# RT58X register map
Series: ARMv8-M Mainline; File version: 1.0
CPU: CM3 r0p0, little endian, MPU, no FPU, VTOR, 3 interrupt priority bits
Registers are 32-bit, read-write, reset 0x0 unless marked. A register's access mark holds for its fields unless they carry their own. Offsets are from the block's base; [hi:lo] are bit positions.

## UART2 — UART2 Register block
Base 0xA0600000
0x00 UART2_THR_RBR_REG — uart2 thr rbr
  [7:0] THR_RBR — For write, data to be transmitted. For read, received data.
    0=B_0_to_7 (For write, data to be transmitted. For read, received data.)
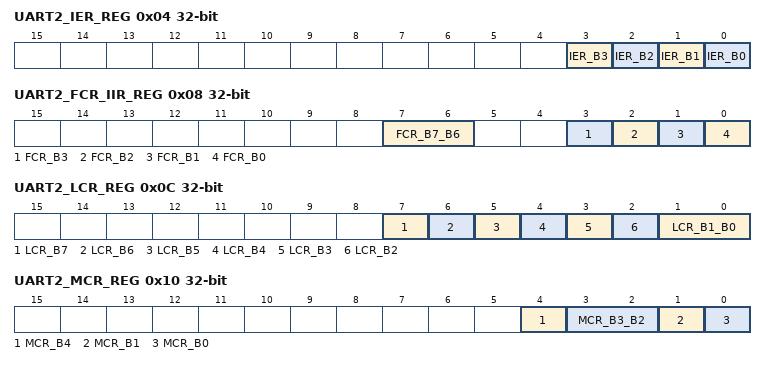
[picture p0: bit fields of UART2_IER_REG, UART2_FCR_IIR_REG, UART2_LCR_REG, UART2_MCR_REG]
0x04 UART2_IER_REG — uart2 ier
  [3] IER_B3 — Enable MODEM Status Interrupt.
    0=B_3 (Enable MODEM Status Interrupt.)
  [2] IER_B2 — Enable Receiver Line Status Interrupt.
    0=B_2 (Enable Receiver Line Status Interrupt.)
  [1] IER_B1 — Enable Transmitter Holding Register Interrupt.
    0=B_1 (Enable Transmitter Holding Register Interrupt.)
  [0] IER_B0 — Enable Received Data Available Interrupt.
    0=B_0 (Enable Received Data Available Interrupt.)
0x08 UART2_FCR_IIR_REG — uart2 fcr iir
  [7:6] FCR_B7_B6 — Receiver Trigger Level.
    0=B_6_to_7 (Receiver Trigger Level.)
  [3] FCR_B3 — DMA Mode Select. Only support 16550 Mode 1.
    0=B_3 (DMA Mode Select. Only support 16550 Mode 1.)
  [2] FCR_B2 — Transmit FIFO reset (self-clearing).
    0=B_2 (Transmit FIFO reset (self-clearing).)
  [1] FCR_B1 — Receive FIFO reset (self-clearing).
    0=B_1 (Receive FIFO reset (self-clearing).)
  [0] FCR_B0 — FIFO Enable.
    0=B_0 (FIFO Enable.)
0x0C UART2_LCR_REG — uart2 lcr
  [7] LCR_B7 — Divisor Latch Access (DLAB).
    0=B_7 (Divisor Latch Access (DLAB).)
  [6] LCR_B6 — Set Break.
    0=B_6 (Set Break.)
  [5] LCR_B5 — Stick Parity.
    0=B_5 (Stick Parity.)
  [4] LCR_B4 — Even Parity Select.
    0=B_4 (Even Parity Select.)
  [3] LCR_B3 — Parity Enable.
    0=B_3 (Parity Enable.)
  [2] LCR_B2 — Number of Stop Bits.
    0=B_2 (Number of Stop Bits.)
  [1:0] LCR_B1_B0 — Word Length Select. 0: 5-bit data 1: 6-bit data 2: 7-bit data 3: 8-bit data
    0=B_0_to_1 (Word Length Select. 0: 5-bit data 1: 6-bit data 2: 7-bit data 3: 8-bit data)
0x10 UART2_MCR_REG — uart2 mcr
  [4] MCR_B4 — Loopback mode select.
    0=B_4 (Loopback mode select.)
  [3:2] MCR_B3_B2 — Auxiliary user designated output.
    0=B_2_to_3 (Auxiliary user designated output.)
  [1] MCR_B1 — Request to Send (RTS).
    0=B_1 (Request to Send (RTS).)
  [0] MCR_B0 — Data Terminal Ready (DTR).
    0=B_0 (Data Terminal Ready (DTR).)
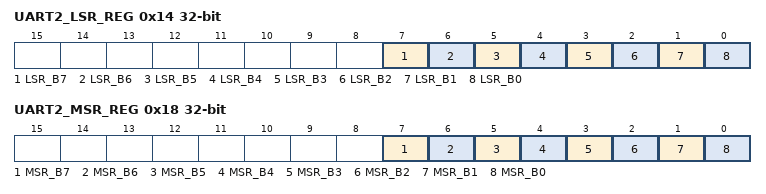
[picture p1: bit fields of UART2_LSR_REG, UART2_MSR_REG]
0x14 UART2_LSR_REG ro — uart2 lsr
  [7] LSR_B7 — Error in Receiver FIFO.
    0=B_7 (Error in Receiver FIFO.)
  [6] LSR_B6 — Transmitter Empty.
    0=B_6 (Transmitter Empty.)
  [5] LSR_B5 — Transmitter Holding Register Empty.
    0=B_5 (Transmitter Holding Register Empty.)
  [4] LSR_B4 — Break Interrupt.
    0=B_4 (Break Interrupt.)
  [3] LSR_B3 — Framing Error.
    0=B_3 (Framing Error.)
  [2] LSR_B2 — Parity Error.
    0=B_2 (Parity Error.)
  [1] LSR_B1 — Overrun Error.
    0=B_1 (Overrun Error.)
  [0] LSR_B0 — Data Ready (DR).
    0=B_0 (Data Ready (DR).)
0x18 UART2_MSR_REG ro — uart2 msr
  [7] MSR_B7 — Data Carrier Detect (DCD).
    0=B_7 (Data Carrier Detect (DCD).)
  [6] MSR_B6 — Ring Indicator (RI).
    0=B_6 (Ring Indicator (RI).)
  [5] MSR_B5 — Data Set Ready (DSR).
    0=B_5 (Data Set Ready (DSR).)
  [4] MSR_B4 — Clear To Send (CTS).
    0=B_4 (Clear To Send (CTS).)
  [3] MSR_B3 — Delta Data Carrier Detect (DDCD).
    0=B_3 (Delta Data Carrier Detect (DDCD).)
  [2] MSR_B2 — Trailing Edge Ring Indicator (TERI).
    0=B_2 (Trailing Edge Ring Indicator (TERI).)
  [1] MSR_B1 — Delta Data Set Ready (DDSR).
    0=B_1 (Delta Data Set Ready (DDSR).)
  [0] MSR_B0 — Delta Clear To Send (DCTS).
    0=B_0 (Delta Clear To Send (DCTS).)
0x1C UART2_SCR_REG — uart2 scr
  [7:0] SCR_B7_B0 — Scratchpad register.
    0=B_0_to_7 (Scratchpad register.)

## TIMER0 — TIMER0 Register block
Base 0xA0700000
0x00 T0_LOAD_REG — The initial value of the timer. Also, the reload value when the timer is in periodic mode.
0x04 T0_VALUE_REG ro — The current value of the timer synchronized to the PCLK domain. Note that in cases where PCLK is slow, this value may significantly differ from the actual internal count.
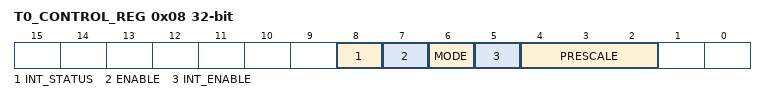
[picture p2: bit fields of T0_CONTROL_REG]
0x08 T0_CONTROL_REG — t0 control
  [8] INT_STATUS ro — Interrupt Status. 0: Timer interrupt is inactive 1: Timer interrupt active.
    0=B_8 (Interrupt Status. 0: Timer interrupt is inactive 1: Timer interrupt active.)
  [7] ENABLE — 0: Timer Disabled 1: Timer Enabled
    0=B_7 (0: Timer Disabled 1: Timer Enabled)
  [6] MODE — 0: Free running mode 1: Periodic mode.
    0=B_6 (0: Free running mode 1: Periodic mode.)
  [5] INT_ENABLE — 0: Timer interrupt disable 1: Timer interrupt enable.
    0=B_5 (0: Timer interrupt disable 1: Timer interrupt enable.)
  [4:2] PRESCALE — 0: clock is divided by one 1: clock is divided by 16 2: clock is divided by 256 3: clock is divided by 2 4: clock is divided by 8 5: clock is divided by 32 6: clock is divided by 128 7: clock is divided by 1024
    0=B_2_to_4 (0: clock is divided by one 1: clock is divided by 16 2: clock is divided by 256 3: clock is divided by 2 4: clock is divided by 8 5: clock is divided by 32 6: clock is divided by 128 7: clock is divided by 1024)
0x0C T0_CLEAR_REG — Clear Interrupt – write any value to clear the timer interrupt.
